# STM32C542 register map
File version: 2.1.0
CPU: CM33 r0p4, little endian, MPU, FPU, 4 interrupt priority bits
Registers are 32-bit, read-write, reset 0x0 unless marked. A register's access mark holds for its fields unless they carry their own. Offsets are from the block's base; [hi:lo] are bit positions; 'fields as' and 'values as' point back to an identical list.

## COMP12 — COMP register block
Base 0x40004000
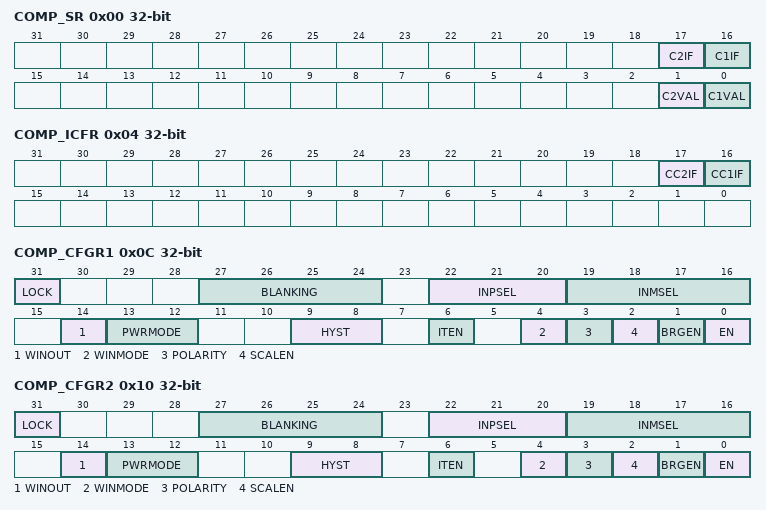
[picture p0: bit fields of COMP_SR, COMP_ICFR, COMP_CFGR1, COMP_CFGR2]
0x00 COMP_SR ro — Comparator status register
  [17] C2IF — COMP2 channel interrupt flag
  [16] C1IF — COMP1 channel interrupt flag
  [1] C2VAL — COMP2 channel output status bit
  [0] C1VAL — COMP1 channel output status bit
0x04 COMP_ICFR — Comparator interrupt clear flag register
  [17] CC2IF — Clear COMP2 channel interrupt flag
  [16] CC1IF — Clear COMP1 channel interrupt flag
0x0C COMP_CFGR1 — Comparator configuration register 1
  [31] LOCK
    0=COMP_CFGR1[31:0] register is read/write; 1=COMP_CFGR1[31:0] is read-only
  [27:24] BLANKING — COMP1 channel blanking source selection
  [22:20] INPSEL — COMP1 non-inverting input selection
  [19:16] INMSEL — COMP1 channel inverting input selection
  [14] WINOUT — COMP1 output selector
    0=COMP1_VALUE; 1=COMP1_VALUE XOR COMP2_VALUE (required for window mode, see Figure152: Window comparators functional block diagram
  [13:12] PWRMODE — Power mode of the COMP1 channel
    0=High speed/high power; 1=Medium speed/medium power
  [9:8] HYST — COMP channel hysteresis selection
    0=No hysteresis; 1=Low hysteresis; 2=Medium hysteresis; 3=High hysteresis
  [6] ITEN — COMP channel interrupt enable
    0=Interrupt generation disabled for COMP channel; 1=Interrupt generation enabled for COMP channel
  [4] WINMODE — COMP1 non-inverting input selector for window mode
    0=Signal selected with INPSEL[1:0]; 1=COMP2_INP signal of COMP2 (required for window mode, see Figure152: Window comparators functional block diagram
  [3] POLARITY — COMP channel polarity selection
    0=COMP channel output is not inverted; 1=COMP channel output is inverted
  [2] SCALEN — Voltage scaler enable
    0=Vless thansub>REFINTless than/sub> scaler disabled; 1=Vless thansub>REFINTless than/sub> scaler enabled
  [1] BRGEN — Scaler bridge enable
    0=Scaler resistor bridge disabled; 1=Scaler resistor bridge enabled
  [0] EN — COMP channel enable
    0=Disable; 1=Enable
0x10 COMP_CFGR2 — Comparator configuration register 2
  [31] LOCK
    0=COMP_CFGR2[31:0] register is read/write; 1=COMP_CFGR2[31:0] is read-only
  [27:24] BLANKING — COMP2 channel blanking source selection
  [22:20] INPSEL — COMP2 non-inverting input selection
  [19:16] INMSEL — COMP2 channel inverting input selection
  [14] WINOUT — COMP2 output selector
    0=COMP2_VALUE; 1=COMP1_VALUE XOR COMP2_VALUE (required for window mode, see Figure152: Window comparators functional block diagram
  [13:12] PWRMODE — Power mode of the COMP2 channel
    0=High speed/high power; 1=Medium speed/medium power
  [9:8] HYST — COMP channel hysteresis selection
    values as COMP_CFGR1.HYST
  [6] ITEN — COMP channel interrupt enable
    values as COMP_CFGR1.ITEN
  [4] WINMODE — COMP2 non-inverting input selector for window mode
    values as COMP_CFGR1.WINMODE
  [3] POLARITY — COMP channel polarity selection
    values as COMP_CFGR1.POLARITY
  [2] SCALEN — Voltage scaler enable
    values as COMP_CFGR1.SCALEN
  [1] BRGEN — Scaler bridge enable
    values as COMP_CFGR1.BRGEN
  [0] EN — COMP channel enable
    0=Disable; 1=Enable

## CRC — CRC address block description
Base 0x40023000
0x00 CRC_DR reset 0xFFFFFFFF — CRC data register
  [31:0] DR — Data register bits
0x04 CRC_IDR — CRC independent data register
  [31:0] IDR — General-purpose 32-bit data register bits
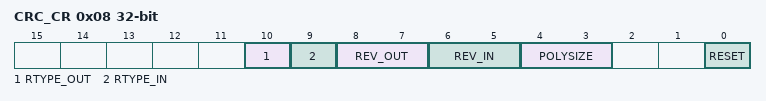
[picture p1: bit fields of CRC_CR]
0x08 CRC_CR — CRC control register
  [10] RTYPE_OUT — Reverse type output This bit controls the reversal granularity of the output data.
    0=Bit level output; 1=Byte or half-word level output
  [9] RTYPE_IN — Reverse type input This bit controls the reversal granularity of the input data.
    0=Bit level input; 1=Byte or half-word level input
  [8:7] REV_OUT — Reverse output data
    0=Bit order not affected; 1=Bit-reversed output format
  [6:5] REV_IN — Reverse input data
    0=Bit order not affected; 1=Bit reversal done by byte; 2=Bit reversal done by half-word; 3=Bit reversal done by word
  [4:3] POLYSIZE — Polynomial size
    0=32 bit polynomial; 1=16 bit polynomial; 2=8 bit polynomial; 3=7 bit polynomial
  [0] RESET — RESET bit
0x10 CRC_INIT reset 0xFFFFFFFF — CRC initial value
  [31:0] CRC_INIT — Programmable initial CRC value
0x14 CRC_POL reset 0x4C11DB7 — CRC polynomial
  [31:0] POL — Programmable polynomial
